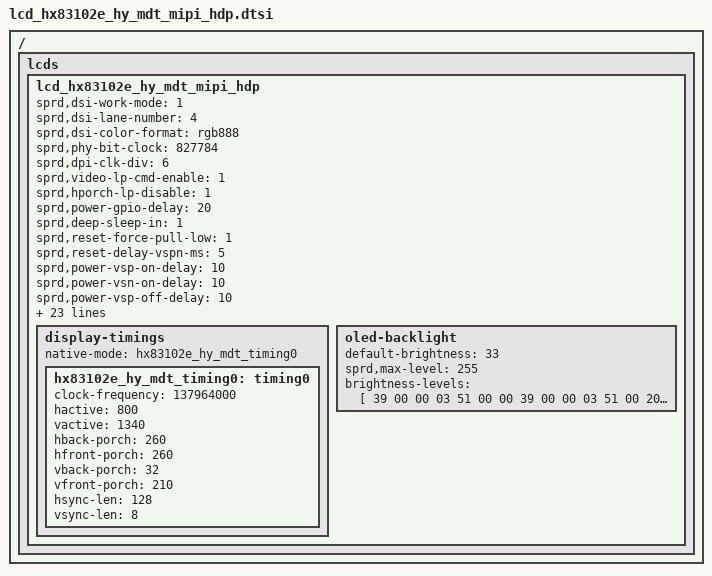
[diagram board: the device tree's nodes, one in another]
/**
*Name：<lcd_hx83102e_hy_mdt_mipi_hdp>
*Author：<huangzhongjie>
*Date：<2022/01/10>
*Purpose：<Tab A7 Lite T618 LCD bring up>
*/
/ {
    fragment {
        target-path = "/";
        __overlay__ {
            lcds {
                lcd_hx83102e_hy_mdt_mipi_hdp: lcd_hx83102e_hy_mdt_mipi_hdp {

                    sprd,dsi-work-mode = <1>; /* video burst mode*/
                    sprd,dsi-lane-number = <4>;
                    sprd,dsi-color-format = "rgb888";

                    sprd,phy-bit-clock = <827784>;    /* kbps */
                    sprd,dpi-clk-div = <6>;
                    sprd,video-lp-cmd-enable = <1>;
                    sprd,hporch-lp-disable = <1>;
                    sprd,power-gpio-delay = <20>;/* ms */
                    sprd,deep-sleep-in = <1>;
                    sprd,reset-force-pull-low = <1>;
                    sprd,reset-delay-vspn-ms = <5>;
                    sprd,power-vsp-on-delay = <10>;
                    sprd,power-vsn-on-delay = <10>;
                    sprd,power-vsp-off-delay = <10>;
                    sprd,power-vsn-off-delay = <10>;

                    sprd,width-mm = <133>;
                    sprd,height-mm = <189>;

                    sprd,reset-on-sequence = <1 5>, <0 5>, <1 60>;
                    sprd,reset-off-sequence = <1 5>;

                    sprd,esd-check-enable = <1>;
                    sprd,esd-check-mode = <0>;
                    sprd,esd-check-reg-count = <1>;
                    sprd,esd-check-register = [0A];
                    sprd,esd-check-value-len = <1>;
                    sprd,esd-check-value = [9D];
                    sprd,esd-check-period = <2000>;

                    sprd,use-dcs-write;
                    sprd,initial-command = [
                        39 00 00 04 B9 83 10 2E
                        39 00 00 05 D1 67 0C FF 05
                        39 00 00 03 D2 2D 2D
                        39 00 00 12 B1 10 FA AF AF 2D 2D B1 6B 43 36 36 36 36 23 21 15 00
                        39 00 00 11 B2 00 20 35 3C 00 26 D2 5E 00 00 00 00 15 20 57 00
                        15 00 00 02 BD 03
                        15 00 00 02 B2 80
                        15 00 00 02 BD 00
                        39 00 00 11 B4 D3 BB C0 C0 D5 D5 68 50 0A DD 09 58 00 FF 00 FF
                        15 00 00 02 E9 CD
                        15 00 00 02 BB 01
                        15 00 00 02 E9 00
                        39 00 00 04 BF FC 85 80
                        39 00 00 09 BA 70 03 A8 83 F2 00 80 0D
                        39 00 00 2C D3 00 00 00 00 01 04 00 00 0C 27 27 73 4F 27 27 04 04 32 10 21 00 21 32 17 A8 00 02 32 15 64 05 64 00 00 21 38 01 55 21 38 01 55 0F
                        39 00 00 2F E0 00 09 15 1D 26 45 5B 61 66 60 75 78 7A 86 82 89 91 A4 A3 51 59 64 73 00 09 15 1D 26 45 5B 61 66 60 75 78 7A 86 82 89 91 A4 A3 51 59 64 73
                        15 00 00 02 BD 01
                        39 00 00 05 B1 01 9B 01 31
                        39 00 00 0A CB 80 36 12 16 C0 28 40 84 22
                        39 00 00 0C D3 01 00 F8 00 00 11 10 00 0A 00 01
                        15 00 00 02 BD 02
                        39 00 00 07 B4 4E 00 33 11 33 88
                        39 00 00 04 BF F2 00 02
                        15 00 00 02 BD 00
                        39 00 00 0F C0 26 26 25 11 A2 10 00 80 00 00 08 00 63 63
                        15 00 00 02 C6 F9
                        15 00 00 02 C7 30
                        39 00 00 09 C8 00 04 04 00 00 82 13 01
                        39 00 00 2D D5 18 18 18 18 19 19 19 19 28 29 28 29 18 18 18 18 1A 1A 1A 1A 1B 1B 1B 1B 06 07 06 07 04 05 04 05 02 03 02 03 00 01 00 01 20 21 20 21
                        39 00 00 2D D6 19 19 19 19 18 18 18 18 21 20 21 20 18 18 18 18 1A 1A 1A 1A 1B 1B 1B 1B 05 04 05 04 07 06 07 06 01 00 01 00 03 02 03 02 29 28 29 28
                        39 00 00 18 E7 12 13 02 02 2E 2E 0E 0E 1A 11 21 AC 1C 71 01 27 00 00 00 00 17 00 68
                        15 00 00 02 BD 01
                        39 00 00 08 E7 01 0C 01 60 0D 88 0E
                        15 00 00 02 BD 02
                        39 00 00 1D E7 FF 01 FD 01 00 00 22 00 00 00 00 00 00 00 00 00 00 00 00 00 00 00 00 00 81 00 02 40
                        15 00 00 02 BD 00
                        39 00 00 04 C2 43 FF 10
                        15 00 00 02 BD 02
                        39 00 00 0D D8 FF FF FF FF FF F0 FF FF FF FF FF F0
                        15 00 00 02 BD 00
                        15 00 00 02 CC 02
                        39 00 00 03 E1 00 01
                        05 46 00 01 11
                        39 00 00 03 51 00 00
                        39 00 00 05 C9 00 0D F0 00
                        15 00 00 02 53 2C
                        39 00 00 04 B9 00 00 00
                        05 14 00 01 29
                    ];

                    sprd,sleep-in-command = [
                        05 14 00 01 28
                        05 78 00 01 10
                    ];

                    sprd,deep-sleep-in-command = [
                        05 14 00 01 28
                        05 78 00 01 10
                        39 00 00 04 B9 83 10 2E
                        15 14 00 02 B1 11
                        39 00 00 04 B9 00 00 00
                    ];

                    sprd,sleep-out-command = [
                        23 32 00 23 11 00
                        23 14 00 23 29 00
                    ];

                    sprd,pwm-diming-off-command = [
                        39 00 00 02 53 24
                    ];

                    display-timings {
                        native-mode = <&hx83102e_hy_mdt_timing0>;
                        hx83102e_hy_mdt_timing0: timing0 {
                        clock-frequency = <137964000>;
                            hactive = <800>;
                            vactive = <1340>;
                            hback-porch = <260>;
                            hfront-porch = <260>;
                            vback-porch = <32>;
                            vfront-porch = <210>;
                            hsync-len = <128>;
                            vsync-len = <8>;
                        };
                    };

                    oled-backlight {
                        default-brightness = <33>;
                        sprd,max-level = <255>;
                        brightness-levels = [
                            39 00 00 03 51 00 00
                            39 00 00 03 51 00 20
                            39 00 00 03 51 00 30
                            39 00 00 03 51 00 40
                            39 00 00 03 51 00 50
                            39 00 00 03 51 00 60
                            39 00 00 03 51 00 70
                            39 00 00 03 51 00 80
                            39 00 00 03 51 00 90
                            39 00 00 03 51 00 A0
                            39 00 00 03 51 00 B0
                            39 00 00 03 51 00 C0
                            39 00 00 03 51 00 D0
                            39 00 00 03 51 00 E0
                            39 00 00 03 51 00 F0
                            39 00 00 03 51 01 00
                            39 00 00 03 51 01 11
                            39 00 00 03 51 01 21
                            39 00 00 03 51 01 31
                            39 00 00 03 51 01 41
                            39 00 00 03 51 01 51
                            39 00 00 03 51 01 61
                            39 00 00 03 51 01 71
                            39 00 00 03 51 01 81
                            39 00 00 03 51 01 91
                            39 00 00 03 51 01 A1
                            39 00 00 03 51 01 B1
                            39 00 00 03 51 01 C1
                            39 00 00 03 51 01 D1
                            39 00 00 03 51 01 E1
                            39 00 00 03 51 01 F1
                            39 00 00 03 51 02 01
                            39 00 00 03 51 02 11
                            39 00 00 03 51 02 22
                            39 00 00 03 51 02 32
                            39 00 00 03 51 02 42
                            39 00 00 03 51 02 52
                            39 00 00 03 51 02 62
                            39 00 00 03 51 02 72
                            39 00 00 03 51 02 82
                            39 00 00 03 51 02 92
                            39 00 00 03 51 02 A2
                            39 00 00 03 51 02 B2
                            39 00 00 03 51 02 C2
                            39 00 00 03 51 02 D2
                            39 00 00 03 51 02 E2
                            39 00 00 03 51 02 F2
                            39 00 00 03 51 03 02
                            39 00 00 03 51 03 12
                            39 00 00 03 51 03 22
                            39 00 00 03 51 03 32
                            39 00 00 03 51 03 43
                            39 00 00 03 51 03 53
                            39 00 00 03 51 03 63
                            39 00 00 03 51 03 73
                            39 00 00 03 51 03 83
                            39 00 00 03 51 03 93
                            39 00 00 03 51 03 A3
                            39 00 00 03 51 03 B3
                            39 00 00 03 51 03 C3
                            39 00 00 03 51 03 D3
                            39 00 00 03 51 03 E3
                            39 00 00 03 51 03 F3
                            39 00 00 03 51 04 03
                            39 00 00 03 51 04 13
                            39 00 00 03 51 04 23
                            39 00 00 03 51 04 33
                            39 00 00 03 51 04 43
                            39 00 00 03 51 04 54
                            39 00 00 03 51 04 64
                            39 00 00 03 51 04 74
                            39 00 00 03 51 04 84
                            39 00 00 03 51 04 94
                            39 00 00 03 51 04 A4
                            39 00 00 03 51 04 B4
                            39 00 00 03 51 04 C4
                            39 00 00 03 51 04 D4
                            39 00 00 03 51 04 E4
                            39 00 00 03 51 04 F4
                            39 00 00 03 51 05 04
                            39 00 00 03 51 05 14
                            39 00 00 03 51 05 24
                            39 00 00 03 51 05 34
                            39 00 00 03 51 05 44
                            39 00 00 03 51 05 54
                            39 00 00 03 51 05 65
                            39 00 00 03 51 05 75
                            39 00 00 03 51 05 85
                            39 00 00 03 51 05 95
                            39 00 00 03 51 05 A5
                            39 00 00 03 51 05 B5
                            39 00 00 03 51 05 C5
                            39 00 00 03 51 05 D5
                            39 00 00 03 51 05 E5
                            39 00 00 03 51 05 F5
                            39 00 00 03 51 06 05
                            39 00 00 03 51 06 15
                            39 00 00 03 51 06 25
                            39 00 00 03 51 06 35
                            39 00 00 03 51 06 45
                            39 00 00 03 51 06 55
                            39 00 00 03 51 06 65
                            39 00 00 03 51 06 76
                            39 00 00 03 51 06 86
                            39 00 00 03 51 06 96
                            39 00 00 03 51 06 A6
                            39 00 00 03 51 06 B6
                            39 00 00 03 51 06 C6
                            39 00 00 03 51 06 D6
                            39 00 00 03 51 06 E6
                            39 00 00 03 51 06 F6
                            39 00 00 03 51 07 06
                            39 00 00 03 51 07 16
                            39 00 00 03 51 07 26
                            39 00 00 03 51 07 36
                            39 00 00 03 51 07 46
                            39 00 00 03 51 07 56
                            39 00 00 03 51 07 66
                            39 00 00 03 51 07 76
                            39 00 00 03 51 07 87
                            39 00 00 03 51 07 97
                            39 00 00 03 51 07 A7
                            39 00 00 03 51 07 B7
                            39 00 00 03 51 07 C7
                            39 00 00 03 51 07 D7
                            39 00 00 03 51 07 E7
                            39 00 00 03 51 07 F7
                            39 00 00 03 51 08 07
                            39 00 00 03 51 08 17
                            39 00 00 03 51 08 27
                            39 00 00 03 51 08 37
                            39 00 00 03 51 08 47
                            39 00 00 03 51 08 57
                            39 00 00 03 51 08 67
                            39 00 00 03 51 08 77
                            39 00 00 03 51 08 87
                            39 00 00 03 51 08 98
                            39 00 00 03 51 08 A8
                            39 00 00 03 51 08 B8
                            39 00 00 03 51 08 C8
                            39 00 00 03 51 08 D8
                            39 00 00 03 51 08 E8
                            39 00 00 03 51 08 F8
                            39 00 00 03 51 09 08
                            39 00 00 03 51 09 18
                            39 00 00 03 51 09 28
                            39 00 00 03 51 09 38
                            39 00 00 03 51 09 48
                            39 00 00 03 51 09 58
                            39 00 00 03 51 09 68
                            39 00 00 03 51 09 78
                            39 00 00 03 51 09 88
                            39 00 00 03 51 09 98
                            39 00 00 03 51 09 A9
                            39 00 00 03 51 09 B9
                            39 00 00 03 51 09 C9
                            39 00 00 03 51 09 D9
                            39 00 00 03 51 09 E9
                            39 00 00 03 51 09 F9
                            39 00 00 03 51 0A 09
                            39 00 00 03 51 0A 19
                            39 00 00 03 51 0A 29
                            39 00 00 03 51 0A 39
                            39 00 00 03 51 0A 49
                            39 00 00 03 51 0A 59
                            39 00 00 03 51 0A 69
                            39 00 00 03 51 0A 79
                            39 00 00 03 51 0A 89
                            39 00 00 03 51 0A 99
                            39 00 00 03 51 0A A9
                            39 00 00 03 51 0A BA
                            39 00 00 03 51 0A CA
                            39 00 00 03 51 0A DA
                            39 00 00 03 51 0A EA
                            39 00 00 03 51 0A FA
                            39 00 00 03 51 0B 0A
                            39 00 00 03 51 0B 1A
                            39 00 00 03 51 0B 2A
                            39 00 00 03 51 0B 3A
                            39 00 00 03 51 0B 4A
                            39 00 00 03 51 0B 5A
                            39 00 00 03 51 0B 6A
                            39 00 00 03 51 0B 7A
                            39 00 00 03 51 0B 8A
                            39 00 00 03 51 0B 9A
                            39 00 00 03 51 0B AA
                            39 00 00 03 51 0B BA
                            39 00 00 03 51 0B CB
                            39 00 00 03 51 0B DB
                            39 00 00 03 51 0B EB
                            39 00 00 03 51 0B FB
                            39 00 00 03 51 0C 0B
                            39 00 00 03 51 0C 1B
                            39 00 00 03 51 0C 2B
                            39 00 00 03 51 0C 3B
                            39 00 00 03 51 0C 4B
                            39 00 00 03 51 0C 5B
                            39 00 00 03 51 0C 6B
                            39 00 00 03 51 0C 7B
                            39 00 00 03 51 0C 8B
                            39 00 00 03 51 0C 9B
                            39 00 00 03 51 0C AB
                            39 00 00 03 51 0C BB
                            39 00 00 03 51 0C CB
                            39 00 00 03 51 0C DC
                            39 00 00 03 51 0C EC
                            39 00 00 03 51 0C FC
                            39 00 00 03 51 0D 0C
                            39 00 00 03 51 0D 1C
                            39 00 00 03 51 0D 2C
                            39 00 00 03 51 0D 3C
                            39 00 00 03 51 0D 4C
                            39 00 00 03 51 0D 5C
                            39 00 00 03 51 0D 6C
                            39 00 00 03 51 0D 7C
                            39 00 00 03 51 0D 8C
                            39 00 00 03 51 0D 9C
                            39 00 00 03 51 0D AC
                            39 00 00 03 51 0D BC
                            39 00 00 03 51 0D CC
                            39 00 00 03 51 0D DC
                            39 00 00 03 51 0D ED
                            39 00 00 03 51 0D FD
                            39 00 00 03 51 0E 0D
                            39 00 00 03 51 0E 1D
                            39 00 00 03 51 0E 2D
                            39 00 00 03 51 0E 3D
                            39 00 00 03 51 0E 4D
                            39 00 00 03 51 0E 5D
                            39 00 00 03 51 0E 6D
                            39 00 00 03 51 0E 7D
                            39 00 00 03 51 0E 8D
                            39 00 00 03 51 0E 9D
                            39 00 00 03 51 0E AD
                            39 00 00 03 51 0E BD
                            39 00 00 03 51 0E CD
                            39 00 00 03 51 0E DD
                            39 00 00 03 51 0E ED
                            39 00 00 03 51 0E FE
                            39 00 00 03 51 0F 0E
                            39 00 00 03 51 0F 1E
                            39 00 00 03 51 0F 2E
                            39 00 00 03 51 0F 3E
                            39 00 00 03 51 0F 4E
                            39 00 00 03 51 0F 5E
                            39 00 00 03 51 0F 6E
                            39 00 00 03 51 0F 7E
                            39 00 00 03 51 0F 8E
                            39 00 00 03 51 0F 9E
                            39 00 00 03 51 0F AE
                            39 00 00 03 51 0F BE
                            39 00 00 03 51 0F CE
                            39 00 00 03 51 0F DE
                            39 00 00 03 51 0F EE
                            39 00 00 03 51 0F FE
                            39 00 00 03 51 0F FE
                        ];
                    };
                };
            };
        };
    };
};
